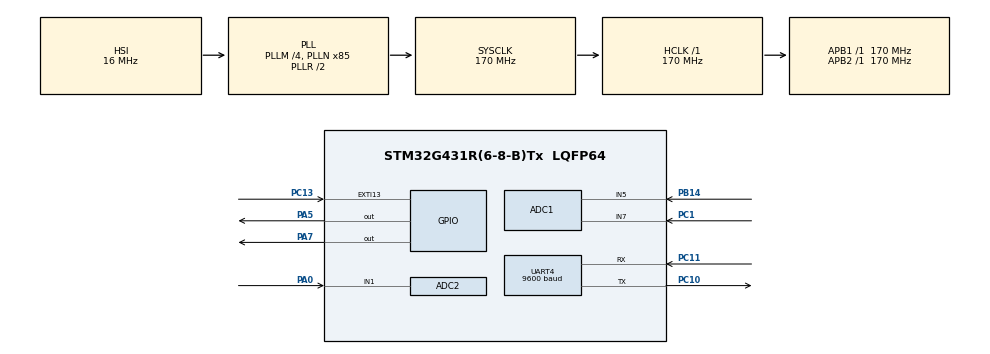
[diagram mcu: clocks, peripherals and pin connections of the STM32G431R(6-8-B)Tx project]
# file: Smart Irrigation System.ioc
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ADC1.Channel-0\#ChannelRegularConversion=ADC_CHANNEL_7
ADC1.Channel-1\#ChannelRegularConversion=ADC_CHANNEL_5
ADC1.ContinuousConvMode=ENABLE
ADC1.NbrOfConversion=2
ADC1.NbrOfConversionFlag=1
ADC1.OffsetNumber-0\#ChannelRegularConversion=ADC_OFFSET_NONE
ADC1.OffsetNumber-1\#ChannelRegularConversion=ADC_OFFSET_NONE
ADC1.Rank-0\#ChannelRegularConversion=1
ADC1.Rank-1\#ChannelRegularConversion=2
ADC1.SamplingTime-0\#ChannelRegularConversion=ADC_SAMPLETIME_2CYCLES_5
ADC1.SamplingTime-1\#ChannelRegularConversion=ADC_SAMPLETIME_92CYCLES_5
ADC1.master=1
ADC2.Channel-0\#ChannelRegularConversion=ADC_CHANNEL_1
ADC2.ContinuousConvMode=ENABLE
ADC2.NbrOfConversionFlag=1
ADC2.OffsetNumber-0\#ChannelRegularConversion=ADC_OFFSET_NONE
ADC2.Rank-0\#ChannelRegularConversion=1
ADC2.SamplingTime-0\#ChannelRegularConversion=ADC_SAMPLETIME_2CYCLES_5
Mcu.Family=STM32G4
Mcu.Name=STM32G431R(6-8-B)Tx
Mcu.Package=LQFP64
NUCLEO-G431RB.BUTTON=1
NUCLEO-G431RB.LD1=true
NUCLEO-G431RB.VCP=true
NVIC.EXTI15_10_IRQn=true\:0\:0\:false\:false\:true\:false\:true\:true
NVIC.PriorityGroup=NVIC_PRIORITYGROUP_4
NVIC.UART4_IRQn=true\:0\:0\:false\:false\:true\:true\:true\:true
PA0.Mode=IN1-Single-Ended
PA0.Signal=ADC2_IN1
PA13.GPIO_Label=T_SWDIO
PA13.Signal=SYS_JTMS-SWDIO
PA14.GPIO_Label=T_SWCLK
PA14.Signal=SYS_JTCK-SWCLK
PA2.Signal=LPUART1_TX
PA3.Signal=LPUART1_RX
PA5.Signal=GPIO_Output
PA7.Signal=GPIO_Output
PB14.Mode=IN5-Single-Ended
PB14.Signal=ADC1_IN5
PB3.GPIO_Label=T_SWO
PB3.Signal=SYS_JTDO-SWO
PC1.Mode=IN7-Single-Ended
PC1.Signal=ADC1_IN7
PC10.Mode=Asynchronous
PC10.Signal=UART4_TX
PC11.Mode=Asynchronous
PC11.Signal=UART4_RX
PC13.Signal=GPXTI13
PC14-OSC32_IN.GPIO_Label=RCC_OSC32_OUT
PC14-OSC32_IN.Signal=RCC_OSC32_IN
PC15-OSC32_OUT.GPIO_Label=RCC_OSC32_OUT
PC15-OSC32_OUT.Signal=RCC_OSC32_OUT
PF0-OSC_IN.GPIO_Label=RCC_OSC_IN
PF0-OSC_IN.Signal=RCC_OSC_IN
PF1-OSC_OUT.GPIO_Label=RCC_OSC_OUT
PF1-OSC_OUT.Signal=RCC_OSC_OUT
ProjectManager.HeapSize=0x200
ProjectManager.StackSize=0x400
ProjectManager.TargetToolchain=STM32CubeIDE
RCC.ADC12Freq_Value=170000000
RCC.AHBFreq_Value=170000000
RCC.APB1Freq_Value=170000000
RCC.APB1TimFreq_Value=170000000
RCC.APB2Freq_Value=170000000
RCC.APB2TimFreq_Value=170000000
RCC.CortexFreq_Value=170000000
RCC.EXTERNAL_CLOCK_VALUE=12288000
RCC.HCLKFreq_Value=170000000
RCC.HSE_VALUE=24000000
RCC.HSI48_VALUE=48000000
RCC.HSI_VALUE=16000000
RCC.LSE_VALUE=32768
RCC.PLLM=RCC_PLLM_DIV4
RCC.PLLN=85
RCC.RTCClockSelection=RCC_RTCCLKSOURCE_LSE
RCC.SYSCLKFreq_VALUE=170000000
RCC.SYSCLKSource=RCC_SYSCLKSOURCE_PLLCLK
RCC.USBFreq_Value=170000000
RCC.VCOOutputFreq_Value=340000000
TIM1.Prescaler=170-1
UART4.BaudRate=9600
VP_NUCLEO-G431RB_VS_BSP_COMMON.Mode=COMMON
VP_SYS_VS_DBSignals.Mode=DisableDeadBatterySignals
VP_TIM1_VS_ClockSourceINT.Mode=Internal
board=NUCLEO-G431RB

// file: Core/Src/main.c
/* USER CODE BEGIN Header */
/**
  ******************************************************************************
  * @file           : main.c
  * @brief          : Main program body
  ******************************************************************************
  * @attention
  *
  * Copyright (c) 2025 STMicroelectronics.
  * All rights reserved.
  *
  * This software is licensed under terms that can be found in the LICENSE file
  * in the root directory of this software component.
  * If no LICENSE file comes with this software, it is provided AS-IS.
  *
  ******************************************************************************
  */
/* USER CODE END Header */
#include "main.h"

/* USER CODE BEGIN Includes */
#include "string.h"
#include<stdio.h>

/* USER CODE END Includes */

COM_InitTypeDef BspCOMInit;
ADC_HandleTypeDef hadc1;
ADC_HandleTypeDef hadc2;

TIM_HandleTypeDef htim1;

UART_HandleTypeDef huart4;

void SystemClock_Config(void);
static void MX_GPIO_Init(void);
static void MX_ADC2_Init(void);
static void MX_ADC1_Init(void);
static void MX_TIM1_Init(void);
static void MX_UART4_Init(void);

/* USER CODE BEGIN 0 */
// --- DEĞİŞKEN TANIMLAMALARI ---
float adc_voltage = 0.0f;    // Işık sensörü voltajı
float adc_voltage2 = 0.0f;   // Toprak nem sensörü voltajı
float adc_voltage3 = 0.0f;   // LM35 sıcaklık sensörü voltajı
float sicaklik = 0.0f,sicaklik2=0.0f;       // Hesaplanan nihai sıcaklık
float nem = 0.0f;            // DHT11'den gelen nem yüzdesi
float data = 0.0f, data2 = 0.0f, data3 = 0.0f; // ADC'den okunan ham (raw) veriler
float isik = 0.0f;           // Yüzde cinsinden ışık miktarı
float toprak_nemi = 0.0f;    // Yüzde cinsinden toprak nemi
uint8_t temp, hum,status;           // DHT11 ham sıcaklık ve nem değerleri
char ch;                     // UART üzerinden gelen kontrol karakteri (O/C)

// Mikro saniye cinsinden gecikme fonksiyonu (DHT11 iletişimi için şart)
void delay_us(uint16_t us)
{
    __HAL_TIM_SET_COUNTER(&htim1, 0); // Sayacı sıfırla
    while (__HAL_TIM_GET_COUNTER(&htim1) < us); // Belirlenen süreye ulaşana kadar bekle
}

// DHT11 pini veri göndermek için çıkış moduna alınır
void DHT11_Pin_Output(void)
{
    GPIO_InitTypeDef GPIO_InitStruct = {0};
    GPIO_InitStruct.Pin = GPIO_PIN_4;
    GPIO_InitStruct.Mode = GPIO_MODE_OUTPUT_PP;
    GPIO_InitStruct.Pull = GPIO_NOPULL;
    GPIO_InitStruct.Speed = GPIO_SPEED_FREQ_LOW;
    HAL_GPIO_Init(GPIOA, &GPIO_InitStruct);
}

// DHT11 pini veri okumak için giriş moduna alınır
void DHT11_Pin_Input(void)
{
    GPIO_InitTypeDef GPIO_InitStruct = {0};
    GPIO_InitStruct.Pin = GPIO_PIN_4;
    GPIO_InitStruct.Mode = GPIO_MODE_INPUT;
    GPIO_InitStruct.Pull = GPIO_NOPULL;
    HAL_GPIO_Init(GPIOA, &GPIO_InitStruct);
}

// DHT11 sensöründen verileri okuyan ana fonksiyon
uint8_t DHT11_Read(uint8_t *temperature, uint8_t *humidity)
{
    uint8_t data[5] = {0}; // 40 bitlik veri bu dizide tutulur
    uint8_t i, j;
    uint32_t timeout;

    // --- BAŞLATMA SİNYALİ ---
    DHT11_Pin_Output();
    HAL_GPIO_WritePin(GPIOA, GPIO_PIN_4, GPIO_PIN_RESET); // Hattı 18ms boyunca sıfıra çek
    HAL_Delay(18);
    HAL_GPIO_WritePin(GPIOA, GPIO_PIN_4, GPIO_PIN_SET);   // Hattı serbest bırak
    delay_us(40);

    DHT11_Pin_Input(); // Sensörün cevap vermesini beklemek için girişe geç

    // Sensörden cevap gelip gelmediğini kontrol eden 'while' döngüleri (Timeout korumalı)
    timeout = 0;
    while (HAL_GPIO_ReadPin(GPIOA, GPIO_PIN_4) == GPIO_PIN_SET)
        if (++timeout > 10000) return 1;

    timeout = 0;
    while (HAL_GPIO_ReadPin(GPIOA, GPIO_PIN_4) == GPIO_PIN_RESET)
        if (++timeout > 10000) return 2;

    timeout = 0;
    while (HAL_GPIO_ReadPin(GPIOA, GPIO_PIN_4) == GPIO_PIN_SET)
        if (++timeout > 10000) return 3;

    // --- 40 BİT VERİ OKUMA ---
    for (j = 0; j < 5; j++)
    {
        for (i = 0; i < 8; i++)
        {
            while (HAL_GPIO_ReadPin(GPIOA, GPIO_PIN_4) == GPIO_PIN_RESET); // Sinyal LOW ise bekle
            delay_us(30); // 30us sonra sinyal hala HIGH ise gelen bit '1'dir

            if (HAL_GPIO_ReadPin(GPIOA, GPIO_PIN_4) == GPIO_PIN_SET)
            {
                data[j] |= (1 << (7 - i)); // İlgili biti 1 yap
                while (HAL_GPIO_ReadPin(GPIOA, GPIO_PIN_4) == GPIO_PIN_SET); // Sinyalin düşmesini bekle
            }
        }
    }

    // Checksum (Hata Kontrolü) doğrulaması
    uint8_t sum = data[0] + data[1] + data[2] + data[3];
    if (sum != data[4]) return 6; // Veri hatalıysa 6 döndür

    *humidity = data[0];    // Nem verisini ata
    *temperature = data[2]; // Sıcaklık verisini ata

    return 0; // Her şey yolunda
}

extern ADC_HandleTypeDef hadc1;
 ADC_ChannelConfTypeDef sConf;

/* USER CODE END 0 */

int main(void)
{

  /* MCU Configuration--------------------------------------------------------*/

  /* Reset of all peripherals, Initializes the Flash interface and the Systick. */
  HAL_Init();

  /* Configure the system clock */
  SystemClock_Config();

  /* Initialize all configured peripherals */
  MX_GPIO_Init();
  MX_ADC2_Init();
  MX_ADC1_Init();
  MX_TIM1_Init();
  MX_UART4_Init();
  /* USER CODE BEGIN 2 */
  HAL_TIM_Base_Start(&htim1); // Mikro saniye gecikmesi için timer başlatıldı

  HAL_UART_Receive_IT(&huart4,&ch,1); // UART üzerinden 1 byte veri beklemek için kesme (interrupt) açıldı

  /* USER CODE END 2 */

  /* Initialize leds */
  BSP_LED_Init(LED_GREEN);

  /* Initialize USER push-button, will be used to trigger an interrupt each time it's pressed.*/
  BSP_PB_Init(BUTTON_USER, BUTTON_MODE_EXTI);

  /* Initialize COM1 port (115200, 8 bits (7-bit data + 1 stop bit), no parity */
  BspCOMInit.BaudRate   = 115200;
  BspCOMInit.WordLength = COM_WORDLENGTH_8B;
  BspCOMInit.StopBits   = COM_STOPBITS_1;
  BspCOMInit.Parity     = COM_PARITY_NONE;
  BspCOMInit.HwFlowCtl  = COM_HWCONTROL_NONE;
  if (BSP_COM_Init(COM1, &BspCOMInit) != BSP_ERROR_NONE)
  {
    Error_Handler();
  }

  /* Infinite loop */
  while (1)
  {

    /* USER CODE BEGIN 3 */

	    // --- 1. SENSÖR: IŞIK (LDR) OKUMA ---
	    sConf.Channel = ADC_CHANNEL_7;
	    sConf.Rank = 1;
	    HAL_ADC_ConfigChannel(&hadc1, &sConf);

	    HAL_ADC_Start(&hadc1);
	    HAL_ADC_PollForConversion(&hadc1, HAL_MAX_DELAY);
	    data = HAL_ADC_GetValue(&hadc1); // Ham ADC değerini al (0-4095 arası)

	    adc_voltage = ((float)data / 4095.0f) * 3.3f; // Voltaj değerine çevir
	    isik = 100 * (3.3f - adc_voltage) / 3.3f;    // Voltajı yüzdeye çevir (Karanlıkta voltaj artar mantığıyla)

	    // --- 2. SENSÖR: TOPRAK NEMİ OKUMA ---
	    sConf.Channel = ADC_CHANNEL_5;
	    sConf.Rank = 2; // Rank 2 olarak ayarlanmış
	    HAL_ADC_ConfigChannel(&hadc1, &sConf);
	    HAL_ADC_PollForConversion(&hadc1, HAL_MAX_DELAY);
	    data2 = HAL_ADC_GetValue(&hadc1);

	    adc_voltage2 = ((float)data2 / 4095.0f) * 3.3f;
	    toprak_nemi = 100 * (3.3f - adc_voltage2) / 3.3f; // Islaklık arttıkça direnç düşer, ters oran hesabı

	    // Toprak zaten nemliyse (0.30 eşik değeri) pompayı koruma amaçlı kapat
	    if(toprak_nemi > 0.30)
	        HAL_GPIO_WritePin(GPIOA, GPIO_PIN_6, GPIO_PIN_RESET);

	    HAL_ADC_Stop(&hadc1);
	    HAL_Delay(20);

	    // --- 3. SENSÖR: LM35 ANALOG SICAKLIK ---
	    HAL_ADC_Start(&hadc2);
	    HAL_ADC_PollForConversion(&hadc2, HAL_MAX_DELAY);
	    data3 = HAL_ADC_GetValue(&hadc2);
	    adc_voltage3 = ((float)data3 / 4095.0f) * 3.3f;

	    sicaklik = adc_voltage3 / 0.010; // LM35'de her 10mV = 1 dereceye denk gelir

	    HAL_ADC_Stop(&hadc2);
	    HAL_Delay(20);

	    // --- 4. SENSÖR: DHT11 DİJİTAL SICAKLIK VE NEM ---
	    status = DHT11_Read(&temp, &hum);

	    if (status == 0) // Eğer okuma başarılıysa
	    {
	        sicaklik2 = temp;
	        // İki sensörden (LM35 ve DHT11) hangisi daha düşük gösteriyorsa güvenli tarafta kalmak için onu alıyor
	        if(sicaklik2 < sicaklik){
	            sicaklik = sicaklik2;
	        }
	        nem = hum;
	    }
	    else // Sensör takılı değilse veya bozuksa değerleri 0 yap
	    {
	        sicaklik2 = 0;
	        nem = 0;
	    }

	    // --- VERİLERİ UART ÜZERİNDEN GÖNDERME ---
	    char mesaj[100];

	    // Eğer toprak kuruysa ve kullanıcı 'O' (Open) komutu gönderdiyse "SİSTEM AÇIK" mesajı gönder

	    sprintf(mesaj, "%d,%d,%d,%d\r\n",(int)nem, (int)isik, (int)sicaklik, (int)toprak_nemi);
	    HAL_UART_Transmit(&huart4, (uint8_t*)mesaj, strlen(mesaj), 100); // Hazırlanan metni gönder
	    HAL_Delay(1000); // 1 saniye bekle ve döngüyü tekrarla
	  }

}
  /* USER CODE END 3 */

void SystemClock_Config(void)
{
  RCC_OscInitTypeDef RCC_OscInitStruct = {0};
  RCC_ClkInitTypeDef RCC_ClkInitStruct = {0};

  /** Configure the main internal regulator output voltage
  */
  HAL_PWREx_ControlVoltageScaling(PWR_REGULATOR_VOLTAGE_SCALE1_BOOST);

  /** Initializes the RCC Oscillators according to the specified parameters
  * in the RCC_OscInitTypeDef structure.
  */
  RCC_OscInitStruct.OscillatorType = RCC_OSCILLATORTYPE_HSI;
  RCC_OscInitStruct.HSIState = RCC_HSI_ON;
  RCC_OscInitStruct.HSICalibrationValue = RCC_HSICALIBRATION_DEFAULT;
  RCC_OscInitStruct.PLL.PLLState = RCC_PLL_ON;
  RCC_OscInitStruct.PLL.PLLSource = RCC_PLLSOURCE_HSI;
  RCC_OscInitStruct.PLL.PLLM = RCC_PLLM_DIV4;
  RCC_OscInitStruct.PLL.PLLN = 85;
  RCC_OscInitStruct.PLL.PLLP = RCC_PLLP_DIV2;
  RCC_OscInitStruct.PLL.PLLQ = RCC_PLLQ_DIV2;
  RCC_OscInitStruct.PLL.PLLR = RCC_PLLR_DIV2;
  if (HAL_RCC_OscConfig(&RCC_OscInitStruct) != HAL_OK)
  {
    Error_Handler();
  }

  /** Initializes the CPU, AHB and APB buses clocks
  */
  RCC_ClkInitStruct.ClockType = RCC_CLOCKTYPE_HCLK|RCC_CLOCKTYPE_SYSCLK
                              |RCC_CLOCKTYPE_PCLK1|RCC_CLOCKTYPE_PCLK2;
  RCC_ClkInitStruct.SYSCLKSource = RCC_SYSCLKSOURCE_PLLCLK;
  RCC_ClkInitStruct.AHBCLKDivider = RCC_SYSCLK_DIV1;
  RCC_ClkInitStruct.APB1CLKDivider = RCC_HCLK_DIV1;
  RCC_ClkInitStruct.APB2CLKDivider = RCC_HCLK_DIV1;

  if (HAL_RCC_ClockConfig(&RCC_ClkInitStruct, FLASH_LATENCY_4) != HAL_OK)
  {
    Error_Handler();
  }
}

static void MX_ADC1_Init(void)
{

  ADC_MultiModeTypeDef multimode = {0};
  ADC_ChannelConfTypeDef sConfig = {0};

  /** Common config
  */
  hadc1.Instance = ADC1;
  hadc1.Init.ClockPrescaler = ADC_CLOCK_SYNC_PCLK_DIV4;
  hadc1.Init.Resolution = ADC_RESOLUTION_12B;
  hadc1.Init.DataAlign = ADC_DATAALIGN_RIGHT;
  hadc1.Init.GainCompensation = 0;
  hadc1.Init.ScanConvMode = ADC_SCAN_ENABLE;
  hadc1.Init.EOCSelection = ADC_EOC_SINGLE_CONV;
  hadc1.Init.LowPowerAutoWait = DISABLE;
  hadc1.Init.ContinuousConvMode = ENABLE;
  hadc1.Init.NbrOfConversion = 2;
  hadc1.Init.DiscontinuousConvMode = DISABLE;
  hadc1.Init.ExternalTrigConv = ADC_SOFTWARE_START;
  hadc1.Init.ExternalTrigConvEdge = ADC_EXTERNALTRIGCONVEDGE_NONE;
  hadc1.Init.DMAContinuousRequests = DISABLE;
  hadc1.Init.Overrun = ADC_OVR_DATA_PRESERVED;
  hadc1.Init.OversamplingMode = DISABLE;
  if (HAL_ADC_Init(&hadc1) != HAL_OK)
  {
    Error_Handler();
  }

  /** Configure the ADC multi-mode
  */
  multimode.Mode = ADC_MODE_INDEPENDENT;
  if (HAL_ADCEx_MultiModeConfigChannel(&hadc1, &multimode) != HAL_OK)
  {
    Error_Handler();
  }

  /** Configure Regular Channel
  */
  sConfig.Channel = ADC_CHANNEL_7;
  sConfig.Rank = ADC_REGULAR_RANK_1;
  sConfig.SamplingTime = ADC_SAMPLETIME_2CYCLES_5;
  sConfig.SingleDiff = ADC_SINGLE_ENDED;
  sConfig.OffsetNumber = ADC_OFFSET_NONE;
  sConfig.Offset = 0;
  if (HAL_ADC_ConfigChannel(&hadc1, &sConfig) != HAL_OK)
  {
    Error_Handler();
  }

  /** Configure Regular Channel
  */
  sConfig.Channel = ADC_CHANNEL_5;
  sConfig.Rank = ADC_REGULAR_RANK_2;
  sConfig.SamplingTime = ADC_SAMPLETIME_92CYCLES_5;
  if (HAL_ADC_ConfigChannel(&hadc1, &sConfig) != HAL_OK)
  {
    Error_Handler();
  }

}

static void MX_ADC2_Init(void)
{

  ADC_ChannelConfTypeDef sConfig = {0};

  /** Common config
  */
  hadc2.Instance = ADC2;
  hadc2.Init.ClockPrescaler = ADC_CLOCK_SYNC_PCLK_DIV4;
  hadc2.Init.Resolution = ADC_RESOLUTION_12B;
  hadc2.Init.DataAlign = ADC_DATAALIGN_RIGHT;
  hadc2.Init.GainCompensation = 0;
  hadc2.Init.ScanConvMode = ADC_SCAN_DISABLE;
  hadc2.Init.EOCSelection = ADC_EOC_SINGLE_CONV;
  hadc2.Init.LowPowerAutoWait = DISABLE;
  hadc2.Init.ContinuousConvMode = DISABLE;
  hadc2.Init.NbrOfConversion = 1;
  hadc2.Init.DiscontinuousConvMode = DISABLE;
  hadc2.Init.ExternalTrigConv = ADC_SOFTWARE_START;
  hadc2.Init.ExternalTrigConvEdge = ADC_EXTERNALTRIGCONVEDGE_NONE;
  hadc2.Init.DMAContinuousRequests = DISABLE;
  hadc2.Init.Overrun = ADC_OVR_DATA_PRESERVED;
  hadc2.Init.OversamplingMode = DISABLE;
  if (HAL_ADC_Init(&hadc2) != HAL_OK)
  {
    Error_Handler();
  }

  /** Configure Regular Channel
  */
  sConfig.Channel = ADC_CHANNEL_1;
  sConfig.Rank = ADC_REGULAR_RANK_1;
  sConfig.SamplingTime = ADC_SAMPLETIME_92CYCLES_5;
  sConfig.SingleDiff = ADC_SINGLE_ENDED;
  sConfig.OffsetNumber = ADC_OFFSET_NONE;
  sConfig.Offset = 0;
  if (HAL_ADC_ConfigChannel(&hadc2, &sConfig) != HAL_OK)
  {
    Error_Handler();
  }

}

static void MX_TIM1_Init(void)
{

  TIM_ClockConfigTypeDef sClockSourceConfig = {0};
  TIM_MasterConfigTypeDef sMasterConfig = {0};

  htim1.Instance = TIM1;
  htim1.Init.Prescaler = 170-1;
  htim1.Init.CounterMode = TIM_COUNTERMODE_UP;
  htim1.Init.Period = 65535;
  htim1.Init.ClockDivision = TIM_CLOCKDIVISION_DIV1;
  htim1.Init.RepetitionCounter = 0;
  htim1.Init.AutoReloadPreload = TIM_AUTORELOAD_PRELOAD_DISABLE;
  if (HAL_TIM_Base_Init(&htim1) != HAL_OK)
  {
    Error_Handler();
  }
  sClockSourceConfig.ClockSource = TIM_CLOCKSOURCE_INTERNAL;
  if (HAL_TIM_ConfigClockSource(&htim1, &sClockSourceConfig) != HAL_OK)
  {
    Error_Handler();
  }
  sMasterConfig.MasterOutputTrigger = TIM_TRGO_RESET;
  sMasterConfig.MasterOutputTrigger2 = TIM_TRGO2_RESET;
  sMasterConfig.MasterSlaveMode = TIM_MASTERSLAVEMODE_DISABLE;
  if (HAL_TIMEx_MasterConfigSynchronization(&htim1, &sMasterConfig) != HAL_OK)
  {
    Error_Handler();
  }

}

static void MX_UART4_Init(void)
{

  huart4.Instance = UART4;
  huart4.Init.BaudRate = 9600;
  huart4.Init.WordLength = UART_WORDLENGTH_8B;
  huart4.Init.StopBits = UART_STOPBITS_1;
  huart4.Init.Parity = UART_PARITY_NONE;
  huart4.Init.Mode = UART_MODE_TX_RX;
  huart4.Init.HwFlowCtl = UART_HWCONTROL_NONE;
  huart4.Init.OverSampling = UART_OVERSAMPLING_16;
  huart4.Init.OneBitSampling = UART_ONE_BIT_SAMPLE_DISABLE;
  huart4.Init.ClockPrescaler = UART_PRESCALER_DIV1;
  huart4.AdvancedInit.AdvFeatureInit = UART_ADVFEATURE_NO_INIT;
  if (HAL_UART_Init(&huart4) != HAL_OK)
  {
    Error_Handler();
  }
  if (HAL_UARTEx_SetTxFifoThreshold(&huart4, UART_TXFIFO_THRESHOLD_1_8) != HAL_OK)
  {
    Error_Handler();
  }
  if (HAL_UARTEx_SetRxFifoThreshold(&huart4, UART_RXFIFO_THRESHOLD_1_8) != HAL_OK)
  {
    Error_Handler();
  }
  if (HAL_UARTEx_DisableFifoMode(&huart4) != HAL_OK)
  {
    Error_Handler();
  }

}

static void MX_GPIO_Init(void)
{
  GPIO_InitTypeDef GPIO_InitStruct = {0};

  /* GPIO Ports Clock Enable */
  __HAL_RCC_GPIOC_CLK_ENABLE();
  __HAL_RCC_GPIOF_CLK_ENABLE();
  __HAL_RCC_GPIOA_CLK_ENABLE();
  __HAL_RCC_GPIOB_CLK_ENABLE();

  /*Configure GPIO pin Output Level */
  HAL_GPIO_WritePin(GPIOA, GPIO_PIN_7, GPIO_PIN_RESET);

  /*Configure GPIO pin : PA4 */
  GPIO_InitStruct.Pin = GPIO_PIN_4;
  GPIO_InitStruct.Mode = GPIO_MODE_INPUT;
  GPIO_InitStruct.Pull = GPIO_NOPULL;
  HAL_GPIO_Init(GPIOA, &GPIO_InitStruct);

  /*Configure GPIO pin : PA7 */
  GPIO_InitStruct.Pin = GPIO_PIN_7;
  GPIO_InitStruct.Mode = GPIO_MODE_OUTPUT_PP;
  GPIO_InitStruct.Pull = GPIO_NOPULL;
  GPIO_InitStruct.Speed = GPIO_SPEED_FREQ_LOW;
  HAL_GPIO_Init(GPIOA, &GPIO_InitStruct);

}

/* USER CODE BEGIN 4 */
/* --- KONTROL MEKANİZMASI (INTERRUPT) --- */
void HAL_UART_RxCpltCallback(UART_HandleTypeDef *huart)
{
  if (huart->Instance == UART4) // UART4'den bir karakter geldiğinde buraya girer
  {

    // Durum 1: Toprak nemli ve kullanıcı AÇMAK istiyor -> Mantıksız, Kapat!
    if(toprak_nemi > 0.30 && (ch == '1')){
         HAL_GPIO_WritePin(GPIOA, GPIO_PIN_7, GPIO_PIN_RESET);

    }
    // Durum 2: Toprak nemli ve kullanıcı KAPATMAK istiyor -> Tamam, Kapat.
    else if (toprak_nemi > 0.30 && (ch =='0')){
        HAL_GPIO_WritePin(GPIOA, GPIO_PIN_7, GPIO_PIN_RESET);

    }
    // Durum 3: Toprak kuru ama kullanıcı KAPATMAK istiyor -> Tamam, Kapat.
    else if (toprak_nemi <= 0.30 && (ch == '0')){
         HAL_GPIO_WritePin(GPIOA, GPIO_PIN_7, GPIO_PIN_RESET);

    }
    // Durum 4: Toprak kuru ve kullanıcı AÇMAK istiyor -> POMPAYI ÇALIŞTIR (PA7 Pinini Set et)
    else if (toprak_nemi <= 0.30 && (ch == '1')){
         HAL_GPIO_WritePin(GPIOA, GPIO_PIN_7, GPIO_PIN_SET);

    }

    HAL_UART_Receive_IT(&huart4, &ch, 1); // Bir sonraki karakteri beklemeye devam et
  }
}

/* USER CODE END 4 */

void Error_Handler(void)
{
  __disable_irq();
  while (1)
  {
  }
}
